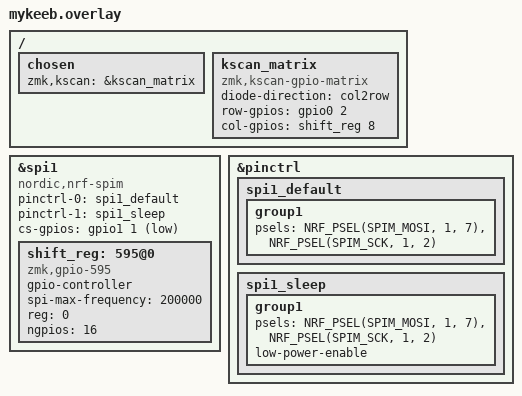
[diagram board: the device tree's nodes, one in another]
/ {
    chosen {
        zmk,kscan = &kscan_matrix;
    };

    kscan_matrix: kscan_matrix {
        compatible = "zmk,kscan-gpio-matrix";
        diode-direction = "col2row";
        
        row-gpios = <&gpio0 2 (GPIO_ACTIVE_HIGH | GPIO_PULL_DOWN)>;
        col-gpios = <&shift_reg 8 GPIO_ACTIVE_HIGH>;
    };
};

&spi1 {
    compatible = "nordic,nrf-spim";
    status = "okay";
    
    pinctrl-0 = <&spi1_default>;
    pinctrl-1 = <&spi1_sleep>;
    pinctrl-names = "default", "sleep";
    cs-gpios = <&gpio1 1 GPIO_ACTIVE_LOW>;
    
    shift_reg: 595@0 {
        compatible = "zmk,gpio-595";
        status = "okay";
        gpio-controller;
        spi-max-frequency = <200000>;
        #gpio-cells = <2>;
        reg = <0>;
        ngpios = <16>;
    };
};

&pinctrl {
    spi1_default: spi1_default {
        group1 {
            psels = <NRF_PSEL(SPIM_MOSI, 1, 7)>, <NRF_PSEL(SPIM_SCK, 1, 2)>;
        };
    };

    spi1_sleep: spi1_sleep {
        group1 {
            psels = <NRF_PSEL(SPIM_MOSI, 1, 7)>, <NRF_PSEL(SPIM_SCK, 1, 2)>;
            low-power-enable;
        };
    };
};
